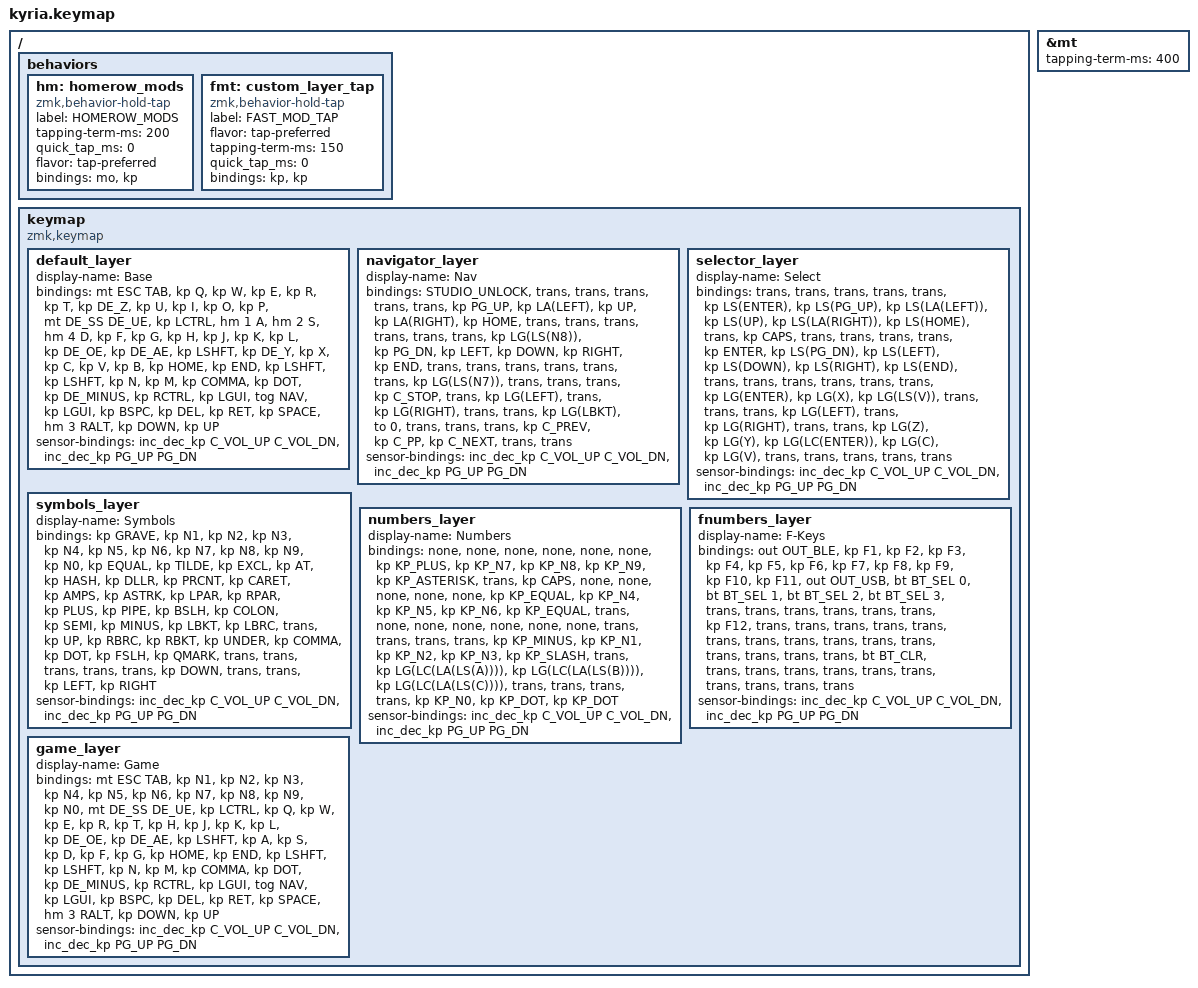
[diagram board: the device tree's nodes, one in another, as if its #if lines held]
/*
 * Copyright (c) 2020 The ZMK Contributors
 *
 * SPDX-License-Identifier: MIT
 */

#include <behaviors.dtsi>
#include <dt-bindings/zmk/keys.h>
#include "keymap-german-rev3.h"
//
#include <dt-bindings/zmk/bt.h>
#include <dt-bindings/zmk/ext_power.h>
#include <dt-bindings/zmk/outputs.h>
									  
									
#ifdef CONFIG_ZMK_STUDIO
#define STUDIO_UNLOCK &studio_unlock
#else
#define STUDIO_UNLOCK &trans
#endif


#define DEFAULT 0
#define NAV 1
#define SELECTOR 2
#define SYMBOLS 3
#define NUMBERS 4
#define FNUMBERS 5
#define GAME 6



&mt {
    tapping-term-ms = <400>;
};

/ {
		behaviors {
	        hm: homerow_mods {
	            compatible = "zmk,behavior-hold-tap";
	            label = "HOMEROW_MODS";
	            #binding-cells = <2>;
	            tapping-term-ms = <200>;
	            quick_tap_ms = <0>;
	            flavor = "tap-preferred";
	            bindings = <&mo>, <&kp>;
	        };
	        fmt: custom_layer_tap {
	            compatible = "zmk,behavior-hold-tap";
	            label = "FAST_MOD_TAP";
	            #binding-cells = <2>;
	            flavor = "tap-preferred";
	            tapping-term-ms = <150>;
	            quick_tap_ms = <0>;
	            bindings = <&kp>, <&kp>;
	        };
	    };


	keymap {
		compatible = "zmk,keymap";

		default_layer {
			display-name = "Base";
/*
 * Base Layer: QWERTZ
 *
 * ,-------------------------------------------.                              ,-------------------------------------------.
 * |TAB/ESC |   Q  |   W  |   E  |   R  |   T  |                              |   Z  |   U  |   I  |   O  |   P  |   Ü/ß  |
 * |--------+------+------+------+------+------|                              |------+------+------+------+------+--------|
 * | LCTR   |A/NAV |S/SEL | D/NUM|   F  |   G  |                              |   H  |   J  |   K  |   L  |   Ö  |    Ä   |
 * |--------+------+------+------+------+------+-------------.  ,-------------+------+------+------+------+------+--------|
 * | LShift |   Y  |   X  |   C  |   V  |   B  | POS1 | END |   |F-keys|  ] } |   N  |   M  |  ,   |   .  |   -  | RShift |
 * `----------------------+------+------+------+------+------|  |------+------+------+------+------+----------------------'	
 *                        |MISION| NAV  | WIN  | BCKSP| ENF  |  | Enter| Space| AltGr|   -  | CAPS |
 *                        |WARRAN| Layer|      |      |      |  |      |      |      | RCTR |      |
 *                        `----------------------------------'  `----------------------------------'
 */

			bindings = <
	&mt ESC TAB   &kp Q &kp W &kp E &kp R &kp T                                                &kp DE_Z &kp U  &kp I     &kp O   &kp P    &mt DE_SS DE_UE
	&kp LCTRL   &hm 1 A &hm 2 S &hm 4 D &kp F &kp G                                                &kp H &kp J  &kp K     &kp L   &kp DE_OE &kp DE_AE
	&kp  LSHFT &kp DE_Y &kp X &kp C &kp V &kp B &kp HOME &kp END        &kp LSHFT &kp LSHFT &kp N &kp M  &kp COMMA &kp DOT &kp DE_MINUS &kp RCTRL
	                 &kp LGUI &tog NAV &kp LGUI &kp BSPC &kp DEL        &kp RET  &kp SPACE  &hm 3 RALT  &kp DOWN &kp UP 
			>;

			sensor-bindings = <&inc_dec_kp C_VOL_UP C_VOL_DN &inc_dec_kp PG_UP PG_DN>;
		
		};

 


		navigator_layer {
			display-name = "Nav";
/*
 * Nav Layer: Media, navigation
 *
 * ,-------------------------------------------.                              ,-------------------------------------------.
 * | Studio |      |      |      |      |      |                              | PgUp | Alt← |   ↑  | Alt→ | Home |        |
 * |--------+------+------+------+------+------|                              |------+------+------+------+------+--------|
 * |        |   x  |      |      |      |Bullet|                              | PgDn |  ←   |   ↓  |   →  | End  |        |
 * |--------+------+------+------+------+------+-------------.  ,-------------+------+------+------+------+------+--------|
 * |        |      |      |      |      |NList |      |      |  |      |Pause |      | Gui← |      | Gui→ |      |        |
 * `----------------------+------+------+------+------+------|  |------+------+------+------+------+----------------------'
 *                        |Ind L |Dev   |      |      |      |  |M Prev|M Play|M Next|      |      |
 *                        |      |Layer |      |      |      |  |      |      |      |      |      |
 *                        `----------------------------------'  `----------------------------------'
 */
			bindings = <
      STUDIO_UNLOCK &trans &trans &trans       &trans       &trans                                                          &kp PG_UP  &kp LA(LEFT) &kp UP   &kp LA(RIGHT) &kp HOME &trans
      &trans &trans &trans &trans       &trans       &kp LG(LS(N8))                                                  &kp PG_DN  &kp LEFT     &kp DOWN &kp RIGHT     &kp END  &trans
      &trans &trans &trans &trans       &trans       &kp LG(LS(N7)) &trans     &trans   &trans     &kp C_STOP &trans     &kp LG(LEFT) &trans   &kp LG(RIGHT) &trans   &trans
                           &kp LG(LBKT) &to 0  &trans  &trans &trans   &kp C_PREV &kp C_PP   &kp C_NEXT &trans       &trans 
			>;

			sensor-bindings = <&inc_dec_kp C_VOL_UP C_VOL_DN &inc_dec_kp PG_UP PG_DN>;
		};


		selector_layer {
			display-name = "Select";
/*
 * Nav Layer: Select, copy/paste  ALL of right side is Shift+
 *
 * ,-------------------------------------------.                              ,-------------------------------------------.
 * |        |      |      |      |      |SEnter|                              | PgUp | Alt← |   ↑  | Alt→ | Home |        |
 * |--------+------+------+------+------+------|                              |------+------+------+------+------+--------|
 * | CAPS   |      |   x  |      |      |Enter |                              | PgDn |  ←   |   ↓  |   →  | End  |        |
 * |--------+------+------+------+------+------+-------------.  ,-------------+------+------+------+------+------+--------|
 * |        |      |      |      |      |GEnter| Cut  |PstClr|  |      |      |      | Gui← |      | Gui→ |      |        |
 * `----------------------+------+------+------+------+------|  |------+------+------+------+------+----------------------'
 *                        | Undo | Redo |Linki |Copy  | Paste|  |      |      |      |      |      |
 *                        |      |      |      |      |      |  |      |      |      |      |      |
 *                        `----------------------------------'  `----------------------------------'
 */
			bindings = <
      &trans   &trans &trans &trans    &trans    &kp LS(ENTER)                                            &kp LS(PG_UP) &kp LS(LA(LEFT)) &kp LS(UP)   &kp LS(LA(RIGHT)) &kp LS(HOME) &trans
      &kp CAPS &trans &trans &trans    &trans    &kp ENTER                                                &kp LS(PG_DN) &kp LS(LEFT)     &kp LS(DOWN) &kp LS(RIGHT)     &kp LS(END)  &trans
      &trans   &trans &trans &trans    &trans    &kp LG(ENTER)     &kp LG(X) &kp LG(LS(V))  &trans &trans &trans        &kp LG(LEFT)     &trans       &kp LG(RIGHT)     &trans       &trans
                             &kp LG(Z) &kp LG(Y) &kp LG(LC(ENTER)) &kp LG(C) &kp LG(V)      &trans &trans &trans        &trans           &trans 
			>;

			sensor-bindings = <&inc_dec_kp C_VOL_UP C_VOL_DN &inc_dec_kp PG_UP PG_DN>;
		};


		symbols_layer {
			display-name = "Symbols";
/*
 * Sym Layer: Numbers and symbols
 *
 * ,-------------------------------------------.                              ,-------------------------------------------.
 * |    `   |  1   |  2   |  3   |  4   |  5   |                              |   6  |  7   |  8   |  9   |  0   |   =    |
 * |--------+------+------+------+------+------|                              |------+------+------+------+------+--------|
 * |    ~   |  !   |  @   |  #   |  $   |  %   |                              |   ^  |  &   |  *   |  (   |  )   |   +    |
 * |--------+------+------+------+------+------+-------------.  ,-------------+------+------+------+------+------+--------|
 * |    |   |   \  |  :   |  ;   |  -   |  [   |  {   |      |  |   ↑  |   }  |   ]  |  _   |  ,   |  .   |  /   |   ?    |
 * `----------------------+------+-------------+------+------|  |------+------+------+------+------+----------------------'
 *                        |      |      |      |      |      |  |   ↓  |      |   x  |  ←   |  →   |
 *                        |      |      |      |      |      |  |      |      |      |      |      |
 *                        `----------------------------------'  `----------------------------------'
 */
			bindings = <
     &kp GRAVE &kp N1   &kp N2    &kp N3   &kp N4    &kp N5                                        &kp N6    &kp N7    &kp N8     &kp N9   &kp N0   &kp EQUAL
     &kp TILDE &kp EXCL &kp AT    &kp HASH &kp DLLR  &kp PRCNT                                     &kp CARET &kp AMPS  &kp ASTRK  &kp LPAR &kp RPAR &kp PLUS
     &kp PIPE  &kp BSLH &kp COLON &kp SEMI &kp MINUS &kp LBKT &kp LBRC &trans    &kp UP   &kp RBRC &kp RBKT  &kp UNDER &kp COMMA  &kp DOT  &kp FSLH &kp QMARK
                                  &trans   &trans    &trans   &trans   &trans    &kp DOWN &trans   &trans    &kp LEFT  &kp RIGHT
			>;

			sensor-bindings = <&inc_dec_kp C_VOL_UP C_VOL_DN &inc_dec_kp PG_UP PG_DN>;
		};


		numbers_layer {
			display-name = "Numbers";
/*
 * NUM Layer: Numbers and symbols
 *
 * ,-------------------------------------------.                              ,-------------------------------------------.
 * |        |      |      |      |      |      |                              |   +  |  7   |  8   |  9   |  *   |        |
 * |--------+------+------+------+------+------|                              |------+------+------+------+------+--------|
 * | CAPS   |      |      |   x  |      |      |                              |   =  |  4   |  5   |  6   |  =   |        |
 * |--------+------+------+------+------+------+-------------.  ,-------------+------+------+------+------+------+--------|
 * |        |      |      |      |      |      |      |      |  |      |      |   -  |  1   |  2   |  3   |  /   |        |
 * `----------------------+------+------+------+------+------|  |------+------+------+------+------+----------------------'
 *                        |Access|Smiley|Thumb |      |      |  |      |      |  0   |  ,   |  .   |
 *                        |      |      |      |      |      |  |      |      |      |      |      |
 *                        `----------------------------------'  `----------------------------------'
 */
			bindings = <
     &none    &none &none &none                 &none                 &none                                                &kp KP_PLUS  &kp KP_N7   &kp KP_N8  &kp KP_N9 &kp KP_ASTERISK  &trans
     &kp CAPS &none &none &none                 &none                 &none                                                &kp KP_EQUAL &kp KP_N4   &kp KP_N5  &kp KP_N6 &kp KP_EQUAL     &trans
     &none    &none &none &none                 &none                 &none                 &trans &trans    &trans &trans &kp KP_MINUS &kp KP_N1   &kp KP_N2  &kp KP_N3 &kp KP_SLASH     &trans
                          &kp LG(LC(LA(LS(A)))) &kp LG(LC(LA(LS(B)))) &kp LG(LC(LA(LS(C)))) &trans &trans    &trans &trans &kp KP_N0    &kp KP_DOT   &kp KP_DOT
			>;

			sensor-bindings = <&inc_dec_kp C_VOL_UP C_VOL_DN &inc_dec_kp PG_UP PG_DN>;
		};

		fnumbers_layer {
			display-name = "F-Keys";
/*
 * Function Layer: Function keys
 *
 * ,-------------------------------------------.                              ,-------------------------------------------.
 * | TOBLE  |  F1  | F2   | F3   | F4   | F5   |                              |  F6  | F7   | F8   | F9   | F10  | F11    |
 * |--------+------+------+------+------+------|                              |------+------+------+------+------+--------|
 * | TOUSB  | BT0  | BT1  | BT2  | BT3  |      |                              |      |      |      |      |      | F12    |
 * +--------+------+------+------+------+------+-------------.  ,-------------+------+------+------+------+------+--------|
 * |        |      |      |      |      |      |      |      |  |   X  |      |      |      |      |      |      | CLR BT |
 * `----------------------+------+------+------+------+------|  |------+------+------+------+------+----------------------'
 *                        |      |      |      |      |      |  |      |      |      |      |      |
 *                        |      |      |      |      |      |  |      |      |      |      |      |
 *                        `----------------------------------'  `----------------------------------'
 */
			bindings = <
      &out OUT_BLE    &kp F1       &kp F2       &kp F3       &kp F4       &kp F5                                  &kp F6 &kp F7 &kp F8 &kp F9 &kp F10 &kp F11
      &out OUT_USB    &bt BT_SEL 0 &bt BT_SEL 1 &bt BT_SEL 2 &bt BT_SEL 3 &trans                                  &trans &trans &trans &trans &trans  &kp F12
      &trans          &trans       &trans       &trans       &trans       &trans &trans &trans    &trans  &trans  &trans &trans &trans &trans &trans  &bt BT_CLR 
                                                &trans       &trans       &trans &trans &trans    &trans  &trans  &trans &trans &trans 
			>;

			sensor-bindings = <&inc_dec_kp C_VOL_UP C_VOL_DN &inc_dec_kp PG_UP PG_DN>;
		};

		game_layer {
			display-name = "Game";
/*
 * Base Layer: GAME
 *
 * ,-------------------------------------------.                              ,-------------------------------------------.
 * |TAB/ESC |   1  |   2  |   3  |   4  |   5  |                              |   6  |   7  |   8   |   9  |   0  |   Ü/ß  |
 * |--------+------+------+------+------+------|                              |------+------+------+------+------+--------|
 * | LCTR   |  Q    |  W  |  E   |   R  |   T  |                              |   H  |   J  |   K  |   L  |   Ö  |    Ä   |
 * |--------+------+------+------+------+------+-------------.  ,-------------+------+------+------+------+------+--------|
 * | LShift |   A  |   S  |   D  |   F  |   G  | POS1 | END |   |F-keys|  ] } |   N  |   M  |  ,   |   .  |   -  | RShift |
 * `----------------------+------+------+------+------+------|  |------+------+------+------+------+----------------------'	
 *                        |MISION| NAV  | WIN  | BCKSP| ENF  |  | Enter| Space| AltGr|   -  | CAPS |
 *                        |WARRAN| Layer|      |      |      |  |      |      |      | RCTR |      |
 *                        `----------------------------------'  `----------------------------------'
 */

			bindings = <
	&mt ESC TAB   &kp N1 &kp N2 &kp N3 &kp N4 &kp N5                                                &kp N6 &kp N7  &kp N8     &kp N9   &kp N0    &mt DE_SS DE_UE
	&kp LCTRL   &kp Q  &kp W &kp E &kp R &kp T                                                &kp H &kp J  &kp K     &kp L   &kp DE_OE &kp DE_AE
	&kp  LSHFT &kp A &kp S &kp D &kp F &kp G &kp HOME &kp END        &kp LSHFT &kp LSHFT &kp N &kp M  &kp COMMA &kp DOT &kp DE_MINUS &kp RCTRL
	                 &kp LGUI &tog NAV &kp LGUI &kp BSPC &kp DEL        &kp RET  &kp SPACE  &hm 3 RALT  &kp DOWN &kp UP 
			>;

			sensor-bindings = <&inc_dec_kp C_VOL_UP C_VOL_DN &inc_dec_kp PG_UP PG_DN>;
		
		};

 

	};
};

